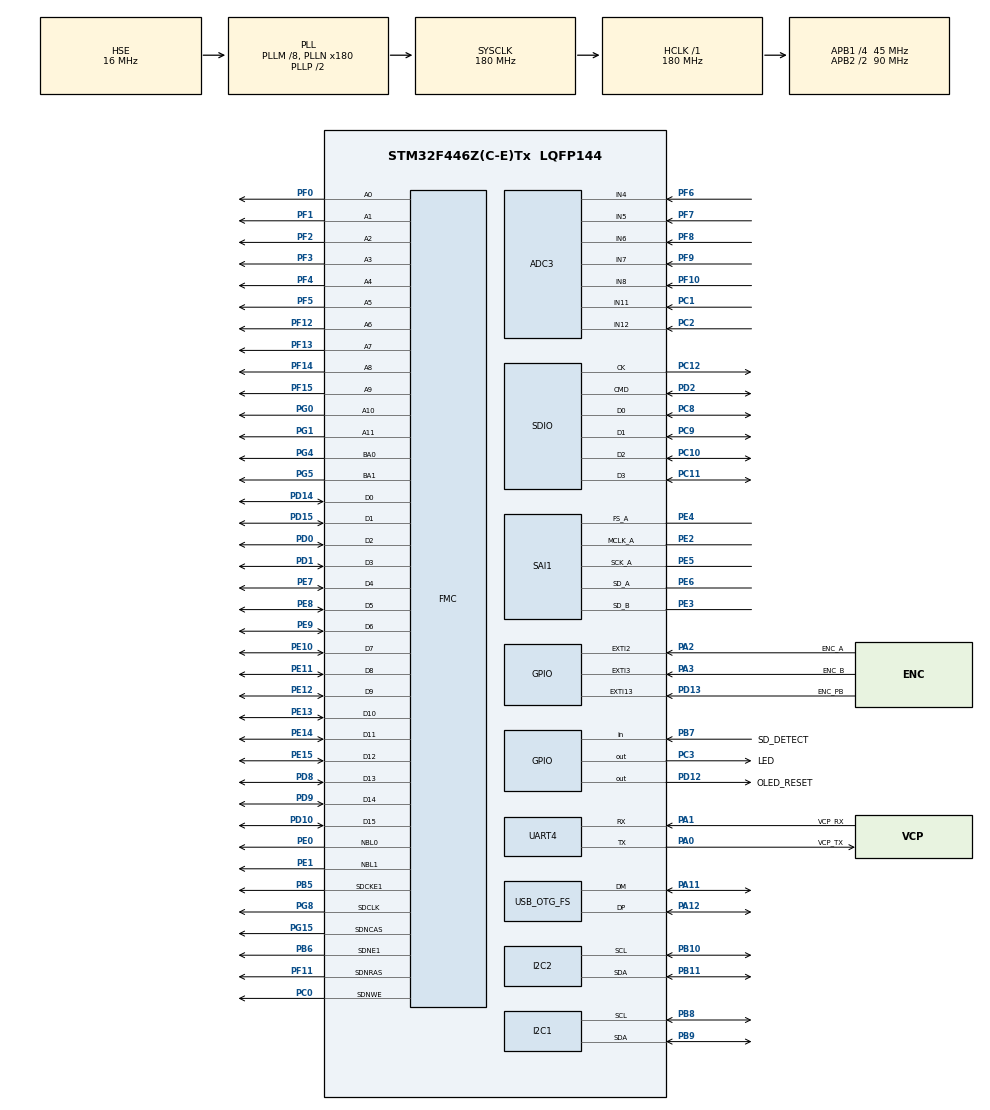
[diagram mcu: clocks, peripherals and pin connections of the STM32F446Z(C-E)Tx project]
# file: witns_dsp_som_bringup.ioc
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ADC3.Channel-0\#ChannelRegularConversion=ADC_CHANNEL_4
ADC3.NbrOfConversionFlag=1
ADC3.Rank-0\#ChannelRegularConversion=1
ADC3.SamplingTime-0\#ChannelRegularConversion=ADC_SAMPLETIME_3CYCLES
Dma.Request0=SAI1_A
Dma.Request1=SAI1_B
Dma.SAI1_A.0.Direction=DMA_MEMORY_TO_PERIPH
Dma.SAI1_A.0.FIFOMode=DMA_FIFOMODE_DISABLE
Dma.SAI1_A.0.Instance=DMA2_Stream1
Dma.SAI1_A.0.MemDataAlignment=DMA_MDATAALIGN_HALFWORD
Dma.SAI1_A.0.MemInc=DMA_MINC_ENABLE
Dma.SAI1_A.0.Mode=DMA_CIRCULAR
Dma.SAI1_A.0.PeriphDataAlignment=DMA_PDATAALIGN_HALFWORD
Dma.SAI1_A.0.PeriphInc=DMA_PINC_DISABLE
Dma.SAI1_A.0.Priority=DMA_PRIORITY_LOW
Dma.SAI1_B.1.Direction=DMA_PERIPH_TO_MEMORY
Dma.SAI1_B.1.FIFOMode=DMA_FIFOMODE_DISABLE
Dma.SAI1_B.1.Instance=DMA2_Stream4
Dma.SAI1_B.1.MemDataAlignment=DMA_MDATAALIGN_HALFWORD
Dma.SAI1_B.1.MemInc=DMA_MINC_ENABLE
Dma.SAI1_B.1.Mode=DMA_CIRCULAR
Dma.SAI1_B.1.PeriphDataAlignment=DMA_PDATAALIGN_HALFWORD
Dma.SAI1_B.1.PeriphInc=DMA_PINC_DISABLE
Dma.SAI1_B.1.Priority=DMA_PRIORITY_LOW
FATFS.BSP.number=1
FATFS.USE_DMA_CODE_SD=0
FATFS._USE_LFN=0
FATFS0.BSP.STBoard=false
FATFS0.BSP.api=Unknown
FATFS0.BSP.instance=PB7
FATFS0.BSP.ip=GPIO
FATFS0.BSP.mode=Input
FATFS0.BSP.name=Detect_SDIO
FATFS0.BSP.solution=PB7
FMC.CASLatency1=FMC_SDRAM_CAS_LATENCY_3
FMC.ExitSelfRefreshDelay1=7
FMC.LoadToActiveDelay1=2
FMC.RCDDelay1=2
FMC.RPDelay1=2
FMC.RPDelay2=2
FMC.ReadPipeDelay1=FMC_SDRAM_RPIPE_DELAY_1
FMC.ReadPipeDelay2=FMC_SDRAM_RPIPE_DELAY_1
FMC.RowCycleDelay1=7
FMC.RowCycleDelay2=7
FMC.SDClockPeriod1=FMC_SDRAM_CLOCK_PERIOD_2
FMC.SDClockPeriod2=FMC_SDRAM_CLOCK_PERIOD_2
FMC.SelfRefreshTime1=4
FMC.WriteRecoveryTime1=3
Mcu.Family=STM32F4
Mcu.Name=STM32F446Z(C-E)Tx
Mcu.Package=LQFP144
NVIC.DMA2_Stream1_IRQn=true\:0\:0\:false\:false\:true\:false\:true\:true
NVIC.DMA2_Stream4_IRQn=true\:0\:0\:false\:false\:true\:false\:true\:true
NVIC.PriorityGroup=NVIC_PRIORITYGROUP_4
NVIC.SAI1_IRQn=true\:0\:0\:false\:false\:true\:true\:true\:true
NVIC.SDIO_IRQn=true\:0\:0\:false\:false\:true\:true\:true\:true
PA0-WKUP.GPIO_Label=VCP_TX
PA0-WKUP.Mode=Asynchronous
PA0-WKUP.Signal=UART4_TX
PA1.GPIO_Label=VCP_RX
PA1.Mode=Asynchronous
PA1.Signal=UART4_RX
PA11.Mode=Device_Only
PA11.Signal=USB_OTG_FS_DM
PA12.Mode=Device_Only
PA12.Signal=USB_OTG_FS_DP
PA13.Mode=Trace_Asynchronous_SW
PA13.Signal=SYS_JTMS-SWDIO
PA14.Mode=Trace_Asynchronous_SW
PA14.Signal=SYS_JTCK-SWCLK
PA2.GPIO_Label=ENC_A
PA2.Signal=GPXTI2
PA3.GPIO_Label=ENC_B
PA3.Signal=GPXTI3
PB10.Mode=I2C
PB10.Signal=I2C2_SCL
PB11.Mode=I2C
PB11.Signal=I2C2_SDA
PB3.Mode=Trace_Asynchronous_SW
PB3.Signal=SYS_JTDO-SWO
PB5.Mode=SdramChipSelect2_1
PB5.Signal=FMC_SDCKE1
PB6.Mode=SdramChipSelect2_1
PB6.Signal=FMC_SDNE1
PB7.GPIO_Label=SD_DETECT
PB7.Signal=GPIO_Input
PB8.Mode=I2C
PB8.Signal=I2C1_SCL
PB9.Mode=I2C
PB9.Signal=I2C1_SDA
PC0.Signal=FMC_SDNWE
PC1.Signal=ADCx_IN11
PC10.Mode=SD_4_bits_Wide_bus
PC10.Signal=SDIO_D2
PC11.Mode=SD_4_bits_Wide_bus
PC11.Signal=SDIO_D3
PC12.Mode=SD_4_bits_Wide_bus
PC12.Signal=SDIO_CK
PC14-OSC32_IN.Mode=LSE-External-Oscillator
PC14-OSC32_IN.Signal=RCC_OSC32_IN
PC15-OSC32_OUT.Mode=LSE-External-Oscillator
PC15-OSC32_OUT.Signal=RCC_OSC32_OUT
PC2.Signal=ADCx_IN12
PC3.GPIO_Label=LED
PC3.Signal=GPIO_Output
PC8.Mode=SD_4_bits_Wide_bus
PC8.Signal=SDIO_D0
PC9.Mode=SD_4_bits_Wide_bus
PC9.Signal=SDIO_D1
PD0.Signal=FMC_D2_DA2
PD1.Signal=FMC_D3_DA3
PD10.Signal=FMC_D15_DA15
PD12.GPIO_Label=OLED_RESET
PD12.Signal=GPIO_Output
PD13.GPIO_Label=ENC_PB
PD13.Signal=GPXTI13
PD14.Signal=FMC_D0_DA0
PD15.Signal=FMC_D1_DA1
PD2.Mode=SD_4_bits_Wide_bus
PD2.Signal=SDIO_CMD
PD8.Signal=FMC_D13_DA13
PD9.Signal=FMC_D14_DA14
PE0.Signal=FMC_NBL0
PE1.Signal=FMC_NBL1
PE10.Signal=FMC_D7_DA7
PE11.Signal=FMC_D8_DA8
PE12.Signal=FMC_D9_DA9
PE13.Signal=FMC_D10_DA10
PE14.Signal=FMC_D11_DA11
PE15.Signal=FMC_D12_DA12
PE2.Mode=SAI_A_MasterWithClock
PE2.Signal=SAI1_MCLK_A
PE3.Mode=SAI_B_SyncSlave
PE3.Signal=SAI1_SD_B
PE4.Mode=SAI_A_MasterWithClock
PE4.Signal=SAI1_FS_A
PE5.Mode=SAI_A_MasterWithClock
PE5.Signal=SAI1_SCK_A
PE6.Mode=SAI_A_MasterWithClock
PE6.Signal=SAI1_SD_A
PE7.Signal=FMC_D4_DA4
PE8.Signal=FMC_D5_DA5
PE9.Signal=FMC_D6_DA6
PF0.Signal=FMC_A0
PF1.Signal=FMC_A1
PF10.Mode=IN8
PF10.Signal=ADC3_IN8
PF11.Signal=FMC_SDNRAS
PF12.Signal=FMC_A6
PF13.Signal=FMC_A7
PF14.Signal=FMC_A8
PF15.Signal=FMC_A9
PF2.Signal=FMC_A2
PF3.Signal=FMC_A3
PF4.Signal=FMC_A4
PF5.Signal=FMC_A5
PF6.Mode=IN4
PF6.Signal=ADC3_IN4
PF7.Mode=IN5
PF7.Signal=ADC3_IN5
PF8.Mode=IN6
PF8.Signal=ADC3_IN6
PF9.Mode=IN7
PF9.Signal=ADC3_IN7
PG0.Signal=FMC_A10
PG1.Signal=FMC_A11
PG15.Signal=FMC_SDNCAS
PG4.Signal=FMC_A14_BA0
PG5.Signal=FMC_A15_BA1
PG8.Signal=FMC_SDCLK
PH0-OSC_IN.Mode=HSE-External-Oscillator
PH0-OSC_IN.Signal=RCC_OSC_IN
PH1-OSC_OUT.Mode=HSE-External-Oscillator
PH1-OSC_OUT.Signal=RCC_OSC_OUT
ProjectManager.HeapSize=0x200
ProjectManager.StackSize=0x400
ProjectManager.TargetToolchain=STM32CubeIDE
RCC.AHBFreq_Value=180000000
RCC.APB1CLKDivider=RCC_HCLK_DIV4
RCC.APB1Freq_Value=45000000
RCC.APB1TimFreq_Value=90000000
RCC.APB2CLKDivider=RCC_HCLK_DIV2
RCC.APB2Freq_Value=90000000
RCC.APB2TimFreq_Value=180000000
RCC.CortexFreq_Value=180000000
RCC.HCLKFreq_Value=180000000
RCC.HSE_VALUE=16000000
RCC.PLLI2SN=123
RCC.PLLI2SQ=10
RCC.PLLM=8
RCC.PLLN=180
RCC.PLLQ=7
RCC.PLLSAIM=8
RCC.PLLSAIN=96
RCC.PLLSAIP=RCC_PLLSAIP_DIV4
RCC.PLLSAIQ=15
RCC.PLLSourceVirtual=RCC_PLLSOURCE_HSE
RCC.SAIACLockSelection=RCC_SAI1CLKSOURCE_PLLI2S
RCC.SYSCLKFreq_VALUE=180000000
RCC.SYSCLKSource=RCC_SYSCLKSOURCE_PLLCLK
RCC.USBCLockSelection=RCC_CLK48CLKSOURCE_PLLSAIP
RCC.USBFreq_Value=48000000
RCC.VCOOutputFreq_Value=360000000
SAI1.AudioFrequency-SAI_A_MasterWithClock=SAI_AUDIO_FREQUENCY_48K
SAI1.ErrorAudioFreq-SAI_A_MasterWithClock=0.09 %
SAI1.InitProtocol-SAI_A_MasterWithClock=Enable
SAI1.InitProtocol-SAI_B_SyncSlave=Enable
SAI1.Instance-SAI_A_MasterWithClock=SAI$Index_Block_A
SAI1.Instance-SAI_B_SyncSlave=SAI$Index_Block_B
SAI1.MClockEnable-SAI_A_MasterWithClock=SAI_MASTERCLOCK_ENABLE
SAI1.RealAudioFreq-SAI_A_MasterWithClock=48.046 KHz
SAI1.VirtualMode-SAI_A_MasterWithClock=VM_MASTER
SAI1.VirtualMode-SAI_B_SyncSlave=VM_SLAVE
SAI1.VirtualProtocol-SAI_A_BASIC=VM_BASIC_PROTOCOL
SAI1.VirtualProtocol-SAI_B_BASIC=VM_BASIC_PROTOCOL
SDIO.ClockDiv=2
SH.ADCx_IN11.0=ADC3_IN11,IN11
SH.ADCx_IN12.0=ADC3_IN12,IN12
SH.FMC_A0.0=FMC_A0,12b-sda1
SH.FMC_A1.0=FMC_A1,12b-sda1
SH.FMC_A10.0=FMC_A10,12b-sda1
SH.FMC_A11.0=FMC_A11,12b-sda1
SH.FMC_A14_BA0.0=FMC_BA0,FourSdramBanks1
SH.FMC_A15_BA1.0=FMC_BA1,FourSdramBanks1
SH.FMC_A2.0=FMC_A2,12b-sda1
SH.FMC_A3.0=FMC_A3,12b-sda1
SH.FMC_A4.0=FMC_A4,12b-sda1
SH.FMC_A5.0=FMC_A5,12b-sda1
SH.FMC_A6.0=FMC_A6,12b-sda1
SH.FMC_A7.0=FMC_A7,12b-sda1
SH.FMC_A8.0=FMC_A8,12b-sda1
SH.FMC_A9.0=FMC_A9,12b-sda1
SH.FMC_D0_DA0.0=FMC_D0,sd-16b-d1
SH.FMC_D10_DA10.0=FMC_D10,sd-16b-d1
SH.FMC_D11_DA11.0=FMC_D11,sd-16b-d1
SH.FMC_D12_DA12.0=FMC_D12,sd-16b-d1
SH.FMC_D13_DA13.0=FMC_D13,sd-16b-d1
SH.FMC_D14_DA14.0=FMC_D14,sd-16b-d1
SH.FMC_D15_DA15.0=FMC_D15,sd-16b-d1
SH.FMC_D1_DA1.0=FMC_D1,sd-16b-d1
SH.FMC_D2_DA2.0=FMC_D2,sd-16b-d1
SH.FMC_D3_DA3.0=FMC_D3,sd-16b-d1
SH.FMC_D4_DA4.0=FMC_D4,sd-16b-d1
SH.FMC_D5_DA5.0=FMC_D5,sd-16b-d1
SH.FMC_D6_DA6.0=FMC_D6,sd-16b-d1
SH.FMC_D7_DA7.0=FMC_D7,sd-16b-d1
SH.FMC_D8_DA8.0=FMC_D8,sd-16b-d1
SH.FMC_D9_DA9.0=FMC_D9,sd-16b-d1
SH.FMC_NBL0.0=FMC_NBL0,Sd2ByteEnable1
SH.FMC_NBL1.0=FMC_NBL1,Sd2ByteEnable1
SH.FMC_SDCLK.0=FMC_SDCLK,12b-sda1
SH.FMC_SDNCAS.0=FMC_SDNCAS,12b-sda1
SH.FMC_SDNRAS.0=FMC_SDNRAS,12b-sda1
SH.FMC_SDNWE.0=FMC_SDNWE,12b-sda1
UART4.VirtualMode=Asynchronous
USB_OTG_FS.VirtualMode=Device_Only
VP_FATFS_VS_SDIO.Mode=SDIO
VP_SAI1_VP_$IpInstance_SAIA_SAI_BASIC.Mode=SAI_A_BASIC
VP_SAI1_VP_$IpInstance_SAIB_SAI_BASIC.Mode=SAI_B_BASIC
board=custom

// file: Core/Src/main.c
/* USER CODE BEGIN Header */
/**
 ******************************************************************************
 * @file           : main.c
 * @brief          : Main program body
 ******************************************************************************
 * @attention
 *
 * Copyright (c) 2025 STMicroelectronics.
 * All rights reserved.
 *
 * This software is licensed under terms that can be found in the LICENSE file
 * in the root directory of this software component.
 * If no LICENSE file comes with this software, it is provided AS-IS.
 *
 ******************************************************************************
 */
/* USER CODE END Header */
#include "main.h"
#include "adc.h"
#include "dma.h"
#include "fatfs.h"
#include "i2c.h"
#include "sai.h"
#include "sdio.h"
#include "usart.h"
#include "usb_otg.h"
#include "gpio.h"
#include "fmc.h"

/* USER CODE BEGIN Includes */
#include <stdio.h>
#include "sgtl5000.h"
#include "ssd1306.h"
#include "ssd1306_tests.h"
#include "ssd1306_fonts.h"
/* USER CODE END Includes */

/* USER CODE BEGIN PD */
#define SAI_TX_BUFFER_LENGTH (480*2)
#define SAI_RX_BUFFER_LENGTH (480*2)
/* USER CODE END PD */

void SystemClock_Config(void);
void PeriphCommonClock_Config(void);
/* USER CODE BEGIN PFP */
static const unsigned char garfield_128x64 [] = {
		0x00, 0x00, 0x00, 0x00, 0x00, 0x00, 0x00, 0x00, 0x00, 0x00, 0x00, 0x00, 0x00, 0x00, 0x00, 0x00,
		0x00, 0x00, 0x00, 0x00, 0x00, 0x07, 0xFF, 0x00, 0x00, 0x00, 0x00, 0x00, 0x00, 0x00, 0x00, 0x00,
		0x00, 0x00, 0x00, 0x00, 0x00, 0x1F, 0xFF, 0xF8, 0x7F, 0xE0, 0x00, 0x00, 0x00, 0x00, 0x00, 0x00,
		0x00, 0x00, 0x00, 0x00, 0x00, 0x3F, 0xFF, 0xCF, 0xFF, 0xFE, 0x00, 0x00, 0x00, 0x00, 0x00, 0x00,
		0x00, 0x00, 0x00, 0x00, 0x00, 0x3F, 0xFB, 0xE3, 0xFF, 0xF3, 0x80, 0x00, 0x00, 0x00, 0x00, 0x00,
		0x00, 0x00, 0x00, 0x00, 0x00, 0x3F, 0xC0, 0xF3, 0xFF, 0xF8, 0xE0, 0x00, 0x00, 0x00, 0x00, 0x00,
		0x00, 0x00, 0x00, 0x00, 0x00, 0x1F, 0x00, 0x1F, 0xD9, 0xFC, 0x38, 0x00, 0x00, 0x00, 0x00, 0x00,
		0x00, 0x00, 0x00, 0x00, 0x00, 0x0D, 0x00, 0x0F, 0x00, 0x1E, 0x0C, 0x00, 0x00, 0x00, 0x00, 0x00,
		0x00, 0x00, 0x00, 0x00, 0x0C, 0x0C, 0x0E, 0x1F, 0xF8, 0x03, 0x04, 0x00, 0x00, 0x00, 0x00, 0x00,
		0x00, 0x00, 0x00, 0x00, 0x03, 0x87, 0xF0, 0x07, 0x00, 0x01, 0x86, 0x00, 0x00, 0x00, 0x00, 0x00,
		0x00, 0x00, 0x00, 0x00, 0x18, 0x3B, 0x80, 0x18, 0x00, 0x30, 0xC3, 0x00, 0x00, 0x00, 0x00, 0x00,
		0x00, 0x00, 0x00, 0x00, 0x00, 0xFE, 0x00, 0x60, 0x00, 0x18, 0xC3, 0x01, 0xC0, 0x00, 0x00, 0x00,
		0x00, 0x00, 0x00, 0x00, 0x3F, 0xFC, 0x01, 0x80, 0x00, 0x0F, 0xC3, 0x8F, 0xC0, 0x00, 0x00, 0x00,
		0x00, 0x00, 0x00, 0x00, 0x07, 0xF0, 0x03, 0x00, 0x00, 0x0C, 0x07, 0xF0, 0x00, 0x00, 0x00, 0x00,
		0x00, 0x00, 0x00, 0x00, 0x0F, 0xE0, 0x0C, 0x00, 0x00, 0x0C, 0x07, 0xFF, 0xF8, 0x00, 0x00, 0x00,
		0x00, 0x00, 0x00, 0x00, 0x38, 0xC0, 0x18, 0x00, 0x00, 0x08, 0x0F, 0xFF, 0xF0, 0x00, 0x00, 0x00,
		0x00, 0x00, 0x00, 0x00, 0x71, 0x80, 0x30, 0x00, 0x00, 0x08, 0x0F, 0xFC, 0xFC, 0x00, 0x00, 0x00,
		0x00, 0x00, 0x00, 0x00, 0xF7, 0x00, 0x60, 0x00, 0x00, 0x18, 0x3F, 0xFE, 0x00, 0x00, 0x00, 0x00,
		0x00, 0x00, 0x00, 0x01, 0xFF, 0x00, 0x60, 0x00, 0x00, 0x18, 0x7F, 0xFE, 0x00, 0x00, 0x00, 0x00,
		0x00, 0x00, 0x00, 0x03, 0xFF, 0x00, 0xC0, 0x00, 0x00, 0x30, 0xFF, 0x1F, 0x00, 0x00, 0x00, 0x00,
		0x00, 0x00, 0x00, 0x03, 0x83, 0xE0, 0xC0, 0x00, 0x00, 0x60, 0x00, 0x03, 0x00, 0x00, 0x00, 0x00,
		0x00, 0x00, 0x00, 0x07, 0x03, 0x1F, 0xFF, 0xFF, 0xFF, 0xC0, 0x00, 0x03, 0x80, 0x00, 0x00, 0x00,
		0x00, 0x00, 0x00, 0x0E, 0x01, 0x00, 0xE7, 0xC0, 0x03, 0x80, 0x00, 0x0F, 0x80, 0x00, 0x00, 0x00,
		0x00, 0x00, 0x00, 0x0F, 0x01, 0x80, 0xE0, 0x00, 0x06, 0x00, 0x00, 0xFF, 0x80, 0x00, 0x00, 0x00,
		0x00, 0x00, 0x00, 0x0F, 0x83, 0x7F, 0xF0, 0x00, 0x38, 0x00, 0x26, 0xFF, 0x80, 0x00, 0x00, 0x00,
		0x00, 0x00, 0x00, 0x0F, 0xDC, 0x18, 0x1F, 0x87, 0xE0, 0x00, 0x26, 0xEF, 0x80, 0x00, 0x00, 0x00,
		0x00, 0x00, 0x00, 0x0F, 0xB8, 0x0E, 0x18, 0x00, 0x30, 0x00, 0x04, 0xCF, 0x80, 0x00, 0x00, 0x00,
		0x00, 0x00, 0x00, 0x0F, 0x30, 0x0F, 0xC0, 0x00, 0x18, 0x00, 0x00, 0x8F, 0x80, 0x00, 0x00, 0x00,
		0x00, 0x00, 0x00, 0x07, 0x30, 0x38, 0x70, 0x00, 0x18, 0x00, 0x00, 0x0F, 0x00, 0x00, 0x00, 0x00,
		0x00, 0x00, 0x00, 0x07, 0x18, 0x00, 0x1F, 0x00, 0x18, 0x3B, 0x80, 0x0E, 0x00, 0x00, 0x00, 0x00,
		0x00, 0x00, 0x00, 0x03, 0x8E, 0x00, 0x03, 0x80, 0x70, 0x1F, 0xF8, 0x1C, 0x00, 0x00, 0x00, 0x00,
		0x00, 0x00, 0x00, 0x01, 0xFF, 0x80, 0x00, 0x03, 0xE0, 0x1F, 0xFF, 0xF8, 0x00, 0x00, 0x00, 0x00,
		0x00, 0x00, 0x00, 0x00, 0x7F, 0x86, 0x00, 0x3F, 0x1F, 0x07, 0xFF, 0xE0, 0x00, 0x00, 0x00, 0x00,
		0x00, 0x00, 0x00, 0x00, 0x0F, 0xC3, 0x00, 0x00, 0x3F, 0x01, 0xFF, 0x80, 0x00, 0x00, 0x00, 0x00,
		0x00, 0x00, 0x00, 0x00, 0x01, 0xFF, 0x80, 0x00, 0x3F, 0xC7, 0xFC, 0x00, 0x00, 0x00, 0x00, 0x00,
		0x00, 0x00, 0x00, 0x00, 0x00, 0x73, 0xE0, 0x07, 0xFF, 0xFF, 0xF8, 0x00, 0x00, 0x00, 0x00, 0x00,
		0x00, 0x00, 0x00, 0x00, 0x00, 0xC0, 0x00, 0x07, 0xC0, 0x3F, 0xF8, 0x00, 0x00, 0x00, 0x00, 0x00,
		0x00, 0x00, 0x00, 0x00, 0x03, 0x00, 0x00, 0x00, 0x00, 0x3F, 0xF8, 0x00, 0x00, 0x00, 0x00, 0x00,
		0x00, 0x00, 0x00, 0x00, 0x0E, 0x00, 0x00, 0x00, 0x00, 0x3E, 0xF8, 0x00, 0x00, 0x00, 0x00, 0x00,
		0x00, 0x00, 0x00, 0x00, 0x18, 0x00, 0x00, 0x00, 0x00, 0xA4, 0xF0, 0x00, 0x00, 0x00, 0x00, 0x00,
		0x00, 0x00, 0x00, 0x00, 0x70, 0x00, 0x00, 0x16, 0x01, 0xC0, 0x78, 0x00, 0x00, 0x00, 0x00, 0x00,
		0x00, 0x00, 0x00, 0x00, 0xE0, 0x00, 0x00, 0x1E, 0x01, 0xC0, 0x3E, 0x00, 0x00, 0x00, 0x00, 0x00,
		0x00, 0x00, 0x00, 0x01, 0xC0, 0x00, 0x00, 0x0C, 0x01, 0x80, 0x3F, 0x00, 0x00, 0x00, 0x00, 0x00,
		0x00, 0x00, 0x00, 0x03, 0x80, 0x00, 0x00, 0x04, 0x01, 0xF3, 0xFF, 0xC0, 0x00, 0x00, 0x00, 0x00,
		0x00, 0x00, 0x00, 0x07, 0x00, 0x00, 0x00, 0x0C, 0x01, 0xEF, 0xF7, 0xE0, 0x00, 0x00, 0x00, 0x00,
		0x00, 0x00, 0x00, 0x0E, 0x00, 0x00, 0x00, 0x18, 0x00, 0x07, 0xF0, 0x60, 0x00, 0x00, 0x00, 0x00,
		0x00, 0x00, 0x00, 0x0C, 0x00, 0x00, 0x00, 0x18, 0x00, 0x07, 0x80, 0x70, 0x00, 0x00, 0x00, 0x00,
		0x00, 0x00, 0x00, 0x18, 0x00, 0x00, 0x00, 0x30, 0x00, 0x06, 0x04, 0xF0, 0x00, 0x00, 0x00, 0x00,
		0x00, 0x00, 0x00, 0x38, 0x00, 0x00, 0x00, 0x60, 0x00, 0x0C, 0x1C, 0xF0, 0x00, 0x00, 0x00, 0x00,
		0x00, 0x00, 0x00, 0x30, 0x00, 0x00, 0x00, 0xC0, 0x00, 0x1F, 0xFF, 0xF0, 0x00, 0x00, 0x00, 0x00,
		0x00, 0x00, 0x00, 0x30, 0x00, 0x00, 0x01, 0x80, 0x00, 0x01, 0xFD, 0xF0, 0x00, 0x00, 0x00, 0x00,
		0x00, 0x00, 0x00, 0x30, 0x00, 0x00, 0x03, 0x00, 0x00, 0x00, 0xFD, 0xF0, 0x00, 0x00, 0x00, 0x00,
		0x00, 0x00, 0x00, 0x30, 0x00, 0x00, 0x07, 0x00, 0x00, 0x01, 0xC1, 0xE0, 0x00, 0x00, 0x00, 0x00,
		0x00, 0x00, 0x00, 0x18, 0x00, 0x00, 0x07, 0x00, 0x00, 0x03, 0x81, 0xE0, 0x00, 0x00, 0x00, 0x00,
		0x00, 0x00, 0x00, 0x0C, 0x00, 0x00, 0x07, 0x00, 0x00, 0x07, 0xFF, 0xC0, 0x00, 0x00, 0x00, 0x00,
		0x00, 0x00, 0x00, 0x06, 0x00, 0x00, 0x03, 0xC0, 0x00, 0x39, 0xFF, 0x80, 0x00, 0x00, 0x00, 0x00,
		0x00, 0x00, 0x00, 0x03, 0x80, 0x00, 0x01, 0xF0, 0x01, 0xE3, 0xFF, 0x00, 0x00, 0x00, 0x00, 0x00,
		0x00, 0x00, 0x00, 0x00, 0xE0, 0x00, 0x00, 0x1F, 0x03, 0x8D, 0xFE, 0x00, 0x00, 0x00, 0x00, 0x00,
		0x00, 0x00, 0x00, 0x00, 0x1E, 0x00, 0x00, 0x03, 0xFC, 0x3D, 0xFE, 0x00, 0x00, 0x00, 0x00, 0x00,
		0x00, 0x00, 0x00, 0x00, 0x01, 0xF8, 0x00, 0x03, 0xC0, 0x3F, 0xFE, 0x00, 0x00, 0x00, 0x00, 0x00,
		0x00, 0x00, 0x00, 0x00, 0x00, 0x07, 0xFF, 0xFF, 0xC0, 0x3F, 0xFE, 0x00, 0x00, 0x00, 0x00, 0x00,
		0x00, 0x00, 0x00, 0x00, 0x00, 0x03, 0xFF, 0xF1, 0xC0, 0x3F, 0xFE, 0x00, 0x00, 0x00, 0x00, 0x00,
		0x00, 0x00, 0x00, 0x00, 0x00, 0x03, 0xFF, 0xE0, 0xC0, 0x3F, 0xFE, 0x00, 0x00, 0x00, 0x00, 0x00,
		0x00, 0x00, 0x00, 0x00, 0x00, 0x03, 0xFF, 0xE0, 0xC0, 0x3F, 0x9E, 0x00, 0x00, 0x00, 0x00, 0x00
};
/* USER CODE END PFP */

/* USER CODE BEGIN 0 */
int __io_putchar(int chr)
{
	HAL_UART_Transmit(&huart4, (uint8_t *)&chr, 1, HAL_MAX_DELAY);
	return chr;
}

FMC_SDRAM_CommandTypeDef command;
#define REFRESH_COUNT       ((uint32_t)0x056A)   /* SDRAM refresh counter (90MHz SDRAM clock) */
#define SDRAM_BANK_ADDR                 ((uint32_t)0xD0000000)

/* #define SDRAM_MEMORY_WIDTH            FMC_SDRAM_MEM_BUS_WIDTH_8 */
#define SDRAM_MEMORY_WIDTH            FMC_SDRAM_MEM_BUS_WIDTH_16

/* #define SDCLOCK_PERIOD                   FMC_SDRAM_CLOCK_PERIOD_2 */
#define SDCLOCK_PERIOD                FMC_SDRAM_CLOCK_PERIOD_3

#define SDRAM_TIMEOUT     ((uint32_t)0xFFFF)

#define SDRAM_MODEREG_BURST_LENGTH_1             ((uint16_t)0x0000)
#define SDRAM_MODEREG_BURST_LENGTH_2             ((uint16_t)0x0001)
#define SDRAM_MODEREG_BURST_LENGTH_4             ((uint16_t)0x0002)
#define SDRAM_MODEREG_BURST_LENGTH_8             ((uint16_t)0x0004)
#define SDRAM_MODEREG_BURST_TYPE_SEQUENTIAL      ((uint16_t)0x0000)
#define SDRAM_MODEREG_BURST_TYPE_INTERLEAVED     ((uint16_t)0x0008)
#define SDRAM_MODEREG_CAS_LATENCY_2              ((uint16_t)0x0020)
#define SDRAM_MODEREG_CAS_LATENCY_3              ((uint16_t)0x0030)
#define SDRAM_MODEREG_OPERATING_MODE_STANDARD    ((uint16_t)0x0000)
#define SDRAM_MODEREG_WRITEBURST_MODE_PROGRAMMED ((uint16_t)0x0000)
#define SDRAM_MODEREG_WRITEBURST_MODE_SINGLE     ((uint16_t)0x0200)

static void SDRAM_Initialization_Sequence(SDRAM_HandleTypeDef *hsdram, FMC_SDRAM_CommandTypeDef *Command)
{
	__IO uint32_t tmpmrd =0;
	/* Step 3:  Configure a clock configuration enable command */
	Command->CommandMode 			 = FMC_SDRAM_CMD_CLK_ENABLE;
	Command->CommandTarget 		 = FMC_SDRAM_CMD_TARGET_BANK2;
	Command->AutoRefreshNumber 	 = 1;
	Command->ModeRegisterDefinition = 0;

	/* Send the command */
	HAL_SDRAM_SendCommand(hsdram, Command, 0x1000);

	/* Step 4: Insert 100 ms delay */
	HAL_Delay(100);

	/* Step 5: Configure a PALL (precharge all) command */
	Command->CommandMode 			 = FMC_SDRAM_CMD_PALL;
	Command->CommandTarget 	     = FMC_SDRAM_CMD_TARGET_BANK2;
	Command->AutoRefreshNumber 	 = 1;
	Command->ModeRegisterDefinition = 0;

	/* Send the command */
	HAL_SDRAM_SendCommand(hsdram, Command, 0x1000);

	/* Step 6 : Configure a Auto-Refresh command */
	Command->CommandMode 			 = FMC_SDRAM_CMD_AUTOREFRESH_MODE;
	Command->CommandTarget 		 = FMC_SDRAM_CMD_TARGET_BANK2;
	Command->AutoRefreshNumber 	 = 4;
	Command->ModeRegisterDefinition = 0;

	/* Send the command */
	HAL_SDRAM_SendCommand(hsdram, Command, 0x1000);

	/* Step 7: Program the external memory mode register */
	tmpmrd = (uint32_t)SDRAM_MODEREG_BURST_LENGTH_2          |
			SDRAM_MODEREG_BURST_TYPE_SEQUENTIAL   |
			SDRAM_MODEREG_CAS_LATENCY_3           |
			SDRAM_MODEREG_OPERATING_MODE_STANDARD |
			SDRAM_MODEREG_WRITEBURST_MODE_SINGLE;

	Command->CommandMode = FMC_SDRAM_CMD_LOAD_MODE;
	Command->CommandTarget 		 = FMC_SDRAM_CMD_TARGET_BANK2;
	Command->AutoRefreshNumber 	 = 1;
	Command->ModeRegisterDefinition = tmpmrd;

	/* Send the command */
	HAL_SDRAM_SendCommand(hsdram, Command, 0x1000);

	/* Step 8: Set the refresh rate counter */
	/* (15.62 us x Freq) - 20 */
	/* (15.62 * 180) - 20 = 2792 */
	/* Set the device refresh counter */
	HAL_SDRAM_ProgramRefreshRate(hsdram, 2792);
	// was 0x056A for 90MHz

}

//uint32_t irq_counter = 0;
//
//void HAL_SAI_TxCpltCallback(SAI_HandleTypeDef *hsai)
//{
//	if (SAI1_Block_A == hsai->Instance)
//	{
//		irq_counter++;
//	}
//}

#define __sdram __attribute__((section(".sdram_data")))

#define AUDIO_BUFFER_LENGTH 2097152	// 8MB
__sdram uint32_t audio_buffer[AUDIO_BUFFER_LENGTH];

//h_sgtl5000_t h_sgtl5000 =
//{
//		.hi2c = &hi2c1,
//		.hsai_tx = &hsai_BlockA1,
//		.hsai_rx = &hsai_BlockB1,
//		.i2c_address = 0x0A
//};

static int16_t sai_tx_buffer[SAI_TX_BUFFER_LENGTH];
static int16_t sai_rx_buffer[SAI_RX_BUFFER_LENGTH];

void list_files(const char *path)
{
	FRESULT res;
	DIR dir;
	FILINFO fno;

#if _USE_LFN
	static char lfn[_MAX_LFN + 1];
	fno.lfname = lfn;
	fno.lfsize = sizeof(lfn);
#endif

	res = f_opendir(&dir, path);  // Ouvre le répertoire
	if (res == FR_OK) {
		while (1) {
			res = f_readdir(&dir, &fno);
			if (res != FR_OK || fno.fname[0] == 0)
				break; // Fin
#if _USE_LFN
			printf("%s%s\n", fno.lfname[0] ? fno.lfname : fno.fname,
					(fno.fattrib & AM_DIR) ? "/" : "");
#else
			printf("%s%s\r\n", fno.fname,
					(fno.fattrib & AM_DIR) ? "/" : "");
#endif
		}
		f_closedir(&dir);
	} else {
		printf("f_opendir error (%d)\r\n", res);
	}
}

void read_text_file(const char *filename)
{
	FIL file;
	FRESULT res;
	char buffer[128];
	UINT bytes_read;

	res = f_open(&file, filename, FA_READ);
	if (res == FR_OK) {
		printf("Reading %s:\r\n", filename);
		do {
			res = f_read(&file, buffer, sizeof(buffer)-1, &bytes_read);
			if (res != FR_OK) break;
			buffer[bytes_read] = '\0';
			printf("%s", buffer);
		} while (bytes_read == sizeof(buffer)-1);
		printf("\r\n-- End of file --\r\n");
		f_close(&file);
	} else {
		printf("f_open error (%d)\r\n", res);
	}
}

static int tx_cplt_counter = 0;
void HAL_SAI_TxCpltCallback(SAI_HandleTypeDef *hsai)
{
	if (SAI1_Block_A == hsai->Instance)
	{
		tx_cplt_counter++;
		// TODO Temp juste pour voir
		//HAL_SAI_DMAStop(&hsai_BlockA2);
	}
}

static int tx_half_cplt_counter = 0;
void HAL_SAI_TxHalfCpltCallback(SAI_HandleTypeDef *hsai)
{
	if (SAI1_Block_A == hsai->Instance)
	{
		tx_half_cplt_counter++;
	}
}

static int rx_cplt_flag = 0;
static int rx_cplt_counter = 0;
void HAL_SAI_RxCpltCallback(SAI_HandleTypeDef *hsai)
{
	if (SAI1_Block_B == hsai->Instance)
	{
		rx_cplt_flag = 1;

		//		for (int i = SAI_RX_BUFFER_LENGTH / 2 ; i < SAI_RX_BUFFER_LENGTH ; i++)
		//		{
		//			sai_tx_buffer[i] = sai_rx_buffer[i];
		//		}

		// TODO Temp juste pour voir
		//HAL_SAI_DMAStop(&hsai_BlockB2);

		rx_cplt_counter++;
	}
}

static int rx_half_cplt_flag = 0;
static int rx_half_cplt_counter = 0;
void HAL_SAI_RxHalfCpltCallback(SAI_HandleTypeDef *hsai)
{
	if (SAI1_Block_B == hsai->Instance)
	{
		rx_half_cplt_flag = 1;

		//		for (int i = 0 ; i < SAI_RX_BUFFER_LENGTH / 2 ; i++)
		//		{
		//			sai_tx_buffer[i] = sai_rx_buffer[i];
		//		}

		rx_half_cplt_counter++;
	}
}

extern FATFS SDFatFS;
/* USER CODE END 0 */

int main(void)
{

  /* MCU Configuration--------------------------------------------------------*/

  /* Reset of all peripherals, Initializes the Flash interface and the Systick. */
  HAL_Init();

  /* Configure the system clock */
  SystemClock_Config();

  /* Configure the peripherals common clocks */
  PeriphCommonClock_Config();

  /* Initialize all configured peripherals */
  MX_GPIO_Init();
  MX_DMA_Init();
  MX_FMC_Init();
  MX_ADC3_Init();
  MX_I2C1_Init();
  MX_SAI1_Init();
  MX_SDIO_SD_Init();
  MX_UART4_Init();
  MX_USB_OTG_FS_PCD_Init();
  MX_FATFS_Init();
  MX_I2C2_Init();
  /* USER CODE BEGIN 2 */
	printf("\r\n==== WITNS DSP SOM ====\r\n");
	HAL_GPIO_WritePin(OLED_RESET_GPIO_Port, OLED_RESET_Pin, GPIO_PIN_SET);

	if (HAL_GPIO_ReadPin(SD_DETECT_GPIO_Port, SD_DETECT_Pin) == GPIO_PIN_RESET)
	{
		printf("SD Card found and initialized\r\n");
	}
	else
	{
		printf("No SD Card found\r\n");
	}

	SDRAM_Initialization_Sequence(&hsdram1, &command);

	//	for (uint32_t i = 0 ; i < SGTL5000_TX_BUFFER_LENGTH ; i+=2)
	//	{
	//		h_sgtl5000.tx_buffer[i] = i * 65536 / SGTL5000_TX_BUFFER_LENGTH;
	//		//		printf("%u\r\n", h_sgtl5000.tx_buffer[i]);
	//	}
	//	for (uint32_t i = 1 ; i < SGTL5000_TX_BUFFER_LENGTH ; i+=2)
	//	{
	//		h_sgtl5000.tx_buffer[i] = 0;
	//		//		printf("%u\r\n", h_sgtl5000.tx_buffer[i]);
	//	}
	//	HAL_StatusTypeDef ret;
	//ssd1306_UpdateScreen();
	//	__HAL_SAI_ENABLE(h_sgtl5000.hsai_tx);
	//	ret = sgtl5000_init(&h_sgtl5000);
	//	//	HAL_StatusTypeDef ret;
	//	//	ret = sgtl5000_enable(&h_sgtl5000);
	//	//	if (ret != HAL_OK)
	//	//	{
	//	//		printf("Error enabling SGTL5000 %d\r\n", ret);
	//	//		Error_Handler();
	//	//	}
	//	//
	//	//	printf("SGTL5000 enabled\r\n");
	//	//
	//	//
	//	//	ret = sgtl5000_line_in_level(&h_sgtl5000, 0, 0);
	//	//	if (ret != HAL_OK)
	//	//	{
	//	//		printf("Error setting line in level %d\r\n", ret);
	//	//		Error_Handler();
	//	//	}
	//	//
	//	//	printf("Line in level set\r\n");
	//	//
	//	//	ret = sgtl5000_line_out_level(&h_sgtl5000, 0, 0);
	//	//	if (ret != HAL_OK)
	//	//	{
	//	//		printf("Error setting line out level %d\r\n", ret);
	//	//		Error_Handler();
	//	//	}
	//	//
	//	//	printf("Line out level set\r\n");
	//	//
	//	//	ret = sgtl5000_unmute(&h_sgtl5000);
	//	//	if (ret != HAL_OK)
	//	//	{
	//	//		printf("Error unmuting SGTL5000 %d\r\n", ret);
	//	//		Error_Handler();
	//	//	}
	//	//
	//	//	printf("SGTL5000 unmuted\r\n");
	//	//
	//	ret = sgtl5000_i2s_start(&h_sgtl5000);
	//	if (ret != HAL_OK)
	//	{
	//		printf("Error starting I2S %d\r\n", ret);
	//		Error_Handler();
	//	}
	//
	//	printf("I2S Started\r\n");
	//
		FATFS fs;
//		FIL file;
		FRESULT res;
//		DIR dir;
//		FILINFO fno;
//		char path[64];

		res = f_mount(&fs, "", 1);  // "" = "0:", 1 = mount now
		if (res != FR_OK) {
			printf("f_mount error (%d)\r\n", res);
		} else {
			printf("SD mounted successfully\r\n");
		}

		list_files("/");
		read_text_file("readme.txt");

	// Starts MCLK but not the LR clock and other signals
	__HAL_SAI_ENABLE(&hsai_BlockA1);

	/**
	 * For the 32 QFN version of the SGTL5000, the I2C device
	 * address is 0n01010(R/W) where n is determined by
	 * CTRL_ADR0_CS and R/W is the read/write bit from the I2C
	 * protocol.
	 *
	 * CTRL_ADR0_CS is tied to GND
	 * Address is 0001010(R/W)
	 * => 00010100 = 0x14 for Write
	 * => 00010101 = 0x15 for Read
	 * Est-ce que le R/W est ajouté dans la HAL ? Dans ce cas :
	 * => 0001010 = 0x0A -> Eh non!
	 * Cela dit, il rajoute le 1 pour la lecture
	 */

	uint16_t sgtl_address = 0x14;
	uint16_t data;

	h_sgtl5000_t h_sgtl5000;
	h_sgtl5000.hi2c = &hi2c1;
	h_sgtl5000.dev_address = sgtl_address;

	sgtl5000_init(&h_sgtl5000);

	HAL_StatusTypeDef ret;
	ret = sgtl5000_i2c_read_register(&h_sgtl5000, SGTL5000_CHIP_ID, &data);

	if (ret != HAL_OK)
	{
		printf("HAL_I2C_Mem_Read error\r\n");
		Error_Handler();
	}

	printf("CHIP ID = 0x%4X\r\n", data);

	for (int i = 0 ; i < SAI_TX_BUFFER_LENGTH ; i++)
	{
		// Generate a sawtooth at 1kHz
		sai_tx_buffer[i] = i * (0xFFFF/SAI_TX_BUFFER_LENGTH);
	}

	printf("Starting SAI...\r\n");
	// Last parameter is the number of DMA CYCLES (here a cycle is 16 bits/2Bytes)
	HAL_SAI_Receive_DMA(&hsai_BlockB1, (uint8_t*) sai_rx_buffer, SAI_RX_BUFFER_LENGTH);
	HAL_SAI_Transmit_DMA(&hsai_BlockA1, (uint8_t*) sai_tx_buffer, SAI_TX_BUFFER_LENGTH);

	//	ssd1306_Init();
	//	ssd1306_SetCursor(2,0);
	//	ssd1306_WriteString("Proute", Font_11x18, White);
	//	ssd1306_UpdateScreen();

	ssd1306_Init();

  /* USER CODE END 2 */

  /* Infinite loop */
  /* USER CODE BEGIN WHILE */
	int i = 0;
#define MOD 20
	while (1)
	{
		HAL_GPIO_TogglePin(LED_GPIO_Port, LED_Pin);
		HAL_Delay(500);

		if (i%MOD == 0)
		{
			ssd1306_SetCursor(2,1);
			ssd1306_WriteString("I hate", Font_16x15, White);
			ssd1306_SetCursor(2,16);
			ssd1306_WriteString("mondays", Font_16x15, White);
			ssd1306_UpdateScreen();
		}

		if (i%MOD == 2)
		{
			ssd1306_Fill(White);
			ssd1306_DrawBitmap(0,0,garfield_128x64,128,64,Black);
			ssd1306_UpdateScreen();
		}

		i++;
		//		if (HAL_GetTick() % 1000 == 0)
		//		{
		//			printf("rx=%d, %d ; tx=%d, %d\r\n",rx_cplt_counter, rx_half_cplt_counter,tx_cplt_counter, tx_half_cplt_counter);
		//		}

    /* USER CODE END WHILE */

	}
}

void SystemClock_Config(void)
{
  RCC_OscInitTypeDef RCC_OscInitStruct = {0};
  RCC_ClkInitTypeDef RCC_ClkInitStruct = {0};

  /** Configure the main internal regulator output voltage
  */
  __HAL_RCC_PWR_CLK_ENABLE();
  __HAL_PWR_VOLTAGESCALING_CONFIG(PWR_REGULATOR_VOLTAGE_SCALE1);

  /** Initializes the RCC Oscillators according to the specified parameters
  * in the RCC_OscInitTypeDef structure.
  */
  RCC_OscInitStruct.OscillatorType = RCC_OSCILLATORTYPE_HSE;
  RCC_OscInitStruct.HSEState = RCC_HSE_ON;
  RCC_OscInitStruct.PLL.PLLState = RCC_PLL_ON;
  RCC_OscInitStruct.PLL.PLLSource = RCC_PLLSOURCE_HSE;
  RCC_OscInitStruct.PLL.PLLM = 8;
  RCC_OscInitStruct.PLL.PLLN = 180;
  RCC_OscInitStruct.PLL.PLLP = RCC_PLLP_DIV2;
  RCC_OscInitStruct.PLL.PLLQ = 7;
  RCC_OscInitStruct.PLL.PLLR = 2;
  if (HAL_RCC_OscConfig(&RCC_OscInitStruct) != HAL_OK)
  {
    Error_Handler();
  }

  /** Activate the Over-Drive mode
  */
  if (HAL_PWREx_EnableOverDrive() != HAL_OK)
  {
    Error_Handler();
  }

  /** Initializes the CPU, AHB and APB buses clocks
  */
  RCC_ClkInitStruct.ClockType = RCC_CLOCKTYPE_HCLK|RCC_CLOCKTYPE_SYSCLK
                              |RCC_CLOCKTYPE_PCLK1|RCC_CLOCKTYPE_PCLK2;
  RCC_ClkInitStruct.SYSCLKSource = RCC_SYSCLKSOURCE_PLLCLK;
  RCC_ClkInitStruct.AHBCLKDivider = RCC_SYSCLK_DIV1;
  RCC_ClkInitStruct.APB1CLKDivider = RCC_HCLK_DIV4;
  RCC_ClkInitStruct.APB2CLKDivider = RCC_HCLK_DIV2;

  if (HAL_RCC_ClockConfig(&RCC_ClkInitStruct, FLASH_LATENCY_5) != HAL_OK)
  {
    Error_Handler();
  }
}

void PeriphCommonClock_Config(void)
{
  RCC_PeriphCLKInitTypeDef PeriphClkInitStruct = {0};

  /** Initializes the peripherals clock
  */
  PeriphClkInitStruct.PeriphClockSelection = RCC_PERIPHCLK_SAI1|RCC_PERIPHCLK_SDIO
                              |RCC_PERIPHCLK_CLK48;
  PeriphClkInitStruct.PLLI2S.PLLI2SN = 123;
  PeriphClkInitStruct.PLLI2S.PLLI2SP = RCC_PLLI2SP_DIV2;
  PeriphClkInitStruct.PLLI2S.PLLI2SM = 16;
  PeriphClkInitStruct.PLLI2S.PLLI2SR = 2;
  PeriphClkInitStruct.PLLI2S.PLLI2SQ = 10;
  PeriphClkInitStruct.PLLSAI.PLLSAIM = 8;
  PeriphClkInitStruct.PLLSAI.PLLSAIN = 96;
  PeriphClkInitStruct.PLLSAI.PLLSAIQ = 15;
  PeriphClkInitStruct.PLLSAI.PLLSAIP = RCC_PLLSAIP_DIV4;
  PeriphClkInitStruct.PLLI2SDivQ = 1;
  PeriphClkInitStruct.PLLSAIDivQ = 1;
  PeriphClkInitStruct.Clk48ClockSelection = RCC_CLK48CLKSOURCE_PLLSAIP;
  PeriphClkInitStruct.SdioClockSelection = RCC_SDIOCLKSOURCE_CLK48;
  PeriphClkInitStruct.Sai1ClockSelection = RCC_SAI1CLKSOURCE_PLLI2S;
  if (HAL_RCCEx_PeriphCLKConfig(&PeriphClkInitStruct) != HAL_OK)
  {
    Error_Handler();
  }
}

void Error_Handler(void)
{
	__disable_irq();
	while (1)
	{
	}
}
